AUTOSAR XML (schema 4-2-2)
package /ARPackage_0
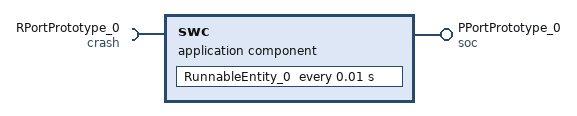
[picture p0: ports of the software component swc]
  application sw component type swc
    provide port PPortPrototype_0: provided-interface=soc
    require port RPortPrototype_0: required-interface=crash
    behavior swc
      timing event TimingEvent_0: start-on-event=RunnableEntity_0, period=0.01
      runnable RunnableEntity_0: symbol=RunnableEntity_0_func
        data-read-access:
          access DRA_DataElements_VariableDataPrototype_0_0: accessed-variable=RPortPrototype_0.DataElements_VariableDataPrototype_0
        data-write-access:
          access DWA_DataElements_VariableDataPrototype_0_0: accessed-variable=PPortPrototype_0.DataElements_VariableDataPrototype_0
